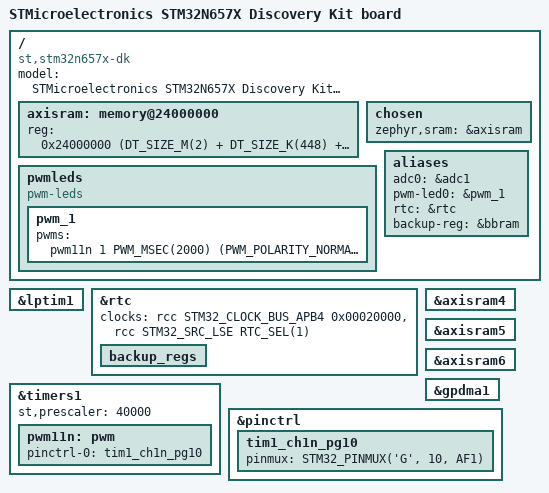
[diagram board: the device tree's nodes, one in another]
/*
 * Copyright (c) 2025 STMicroelectronics
 * Copyright (c) 2025 HU Inc.
 *
 * SPDX-License-Identifier: Apache-2.0
 */

/dts-v1/;
#include "stm32n657x_dk_common.dtsi"

/ {
	model = "STMicroelectronics STM32N657X Discovery Kit board";
	compatible = "st,stm32n657x-dk";

	axisram: memory@24000000 {
		/* This section is the RAM available to the chainloaded application */
		/* 400 kB of FLEXRAM followed by 624 kB of AXISRAM1 + AXISRAM2 */
		reg = <0x24000000 (DT_SIZE_M(2)
			+ DT_SIZE_K(448)
			+ DT_SIZE_K(448)
			+ DT_SIZE_K(448)
			+ DT_SIZE_K(448)
		)>;
	};

	chosen {
		zephyr,sram = &axisram;
	};
	pwmleds {
		compatible = "pwm-leds";
		pwm_1: pwm_1 {
			pwms = <&pwm11n 1 PWM_MSEC(2000) (PWM_POLARITY_NORMAL | STM32_PWM_COMPLEMENTARY)>;
		};
	};
	aliases {
		//volt-sensor0 = &vref;
		adc0 = &adc1;
		pwm-led0 = &pwm_1;
		rtc = &rtc;
		backup-reg = &bbram;
	};
};

stm32_lp_tick_source: &lptim1 {
	status = "okay";
};

&rtc {
	clocks = <&rcc STM32_CLOCK_BUS_APB4 0x00020000>,
		 <&rcc STM32_SRC_LSE RTC_SEL(1)>;
	status = "okay";

	backup_regs {
		status = "okay";
	};
};

&axisram4 {
	status = "okay";
};
&axisram5 {
	status = "okay";
};
&axisram6 {
	status = "okay";
};

&timers1 {
	status = "okay";
	st,prescaler = <40000>;
	pwm11n: pwm {
		status = "okay";
		pinctrl-0 = <&tim1_ch1n_pg10>;
		pinctrl-names = "default";
	};
};

&gpdma1 {
    status = "okay";
};

&pinctrl {
	tim1_ch1n_pg10: tim1_ch1n_pg10 {
		pinmux = <STM32_PINMUX('G', 10, AF1)>;
	};
};
